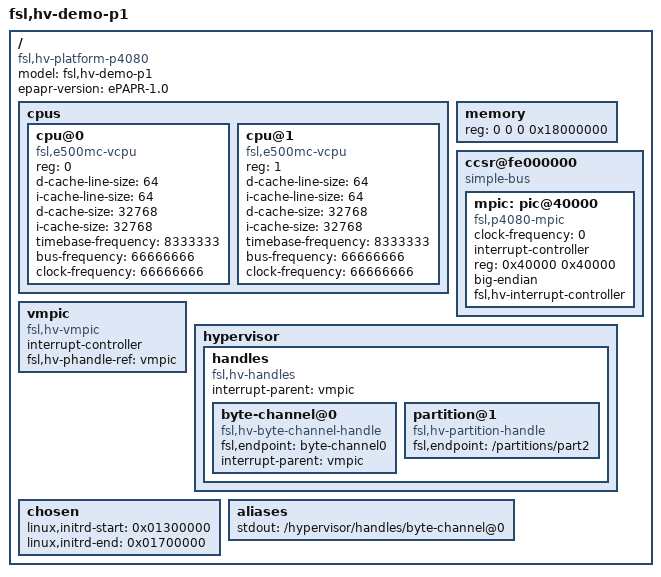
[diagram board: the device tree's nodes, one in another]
/dts-v1/;

/ {
	compatible = "fsl,hv-platform-p4080";
	model = "fsl,hv-demo-p1";
	epapr-version = "ePAPR-1.0";
	#address-cells = <2>;
	#size-cells = <2>;

	cpus {
		#address-cells = <1>;
		#size-cells = <0>;

		cpu@0 {
			device_type = "cpu";
			compatible = "fsl,e500mc-vcpu";
			reg = <0>;
			d-cache-line-size = <64>;
			i-cache-line-size = <64>;
			d-cache-size = <32768>;
			i-cache-size = <32768>;
			timebase-frequency = <8333333>;
			bus-frequency = <66666666>;
			clock-frequency = <66666666>;
		};

		cpu@1 {
			device_type = "cpu";
			compatible = "fsl,e500mc-vcpu";
			reg = <1>;
			d-cache-line-size = <64>;
			i-cache-line-size = <64>;
			d-cache-size = <32768>;
			i-cache-size = <32768>;
			timebase-frequency = <8333333>;
			bus-frequency = <66666666>;
			clock-frequency = <66666666>;
		};
	};
	
	memory {
		reg = <0 0 0 0x18000000>;
		device_type = "memory";
	};
	
	ccsr@fe000000 {
		#address-cells = <1>;
		#size-cells = <1>;
		compatible = "simple-bus";
		device_type = "soc";
		ranges = <0 0 0xfe000000 0x400000>;

		mpic: pic@40000 {
			clock-frequency = <0>;
			interrupt-controller;
			#address-cells = <0>;
			#interrupt-cells = <2>;
			reg = <0x40000 0x40000>;
			compatible = "fsl,p4080-mpic", "fsl,mpic",
			             "chrp,open-pic";
			device_type = "open-pic";
			big-endian;
			fsl,hv-interrupt-controller;
		};
	};

	vmpic:vmpic {
		compatible = "fsl,hv-vmpic";
		interrupt-controller;
		#interrupt-cells = <2>;
		fsl,hv-phandle-ref = <&vmpic>;
	};

	hypervisor {
		handles {
			#address-cells = <1>;
			#size-cells = <0>;
			compatible = "fsl,hv-handles";
			interrupt-parent = <&vmpic>;
			
			byte-channel@0 {
				compatible = "fsl,hv-byte-channel-handle";
				fsl,endpoint = "byte-channel0";
				interrupt-parent = <&vmpic>;
			};
	
			partition@1 {
				compatible = "fsl,hv-partition-handle";
				fsl,endpoint = "/partitions/part2";
			};
		};
	};

	chosen {
		linux,initrd-start = <0x01300000>;
		linux,initrd-end = <0x01700000>;
	};

	aliases {
		stdout = "/hypervisor/handles/byte-channel@0";
	};
};
